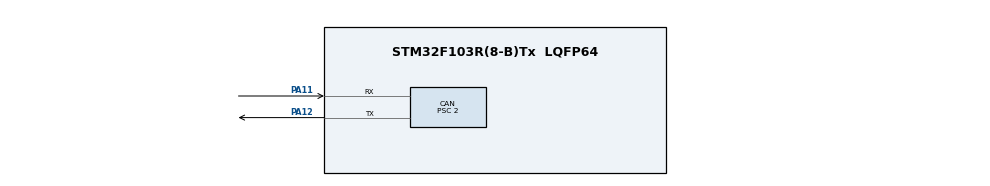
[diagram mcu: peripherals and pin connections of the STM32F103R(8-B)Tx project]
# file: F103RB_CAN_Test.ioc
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CAN.BS1=CAN_BS1_4TQ
CAN.BS2=CAN_BS2_3TQ
CAN.CalculateBaudRate=500000
CAN.CalculateTimeBit=2000.00
CAN.CalculateTimeQuantum=250.0
CAN.Mode=CAN_MODE_LOOPBACK
CAN.Prescaler=2
Mcu.Family=STM32F1
Mcu.Name=STM32F103R(8-B)Tx
Mcu.Package=LQFP64
NVIC.PriorityGroup=NVIC_PRIORITYGROUP_4
NVIC.USB_LP_CAN1_RX0_IRQn=true\:0\:0\:false\:false\:true\:true\:true
PA11.Mode=CAN_Activate
PA11.Signal=CAN_RX
PA12.Mode=CAN_Activate
PA12.Signal=CAN_TX
PA13.Mode=Trace_Asynchronous_SW
PA13.Signal=SYS_JTMS-SWDIO
PA14.Mode=Trace_Asynchronous_SW
PA14.Signal=SYS_JTCK-SWCLK
PB3.Mode=Trace_Asynchronous_SW
PB3.Signal=SYS_JTDO-TRACESWO
ProjectManager.HeapSize=0x200
ProjectManager.StackSize=0x400
ProjectManager.TargetToolchain=STM32CubeIDE
RCC.APB1Freq_Value=8000000
RCC.APB2Freq_Value=8000000
board=custom

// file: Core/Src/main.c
/* USER CODE BEGIN Header */
/**
  ******************************************************************************
  * @file           : main.c
  * @brief          : Main program body
  ******************************************************************************
  * @attention
  *
  * <h2><center>&copy; Copyright (c) 2022 STMicroelectronics.
  * All rights reserved.</center></h2>
  *
  * This software component is licensed by ST under BSD 3-Clause license,
  * the "License"; You may not use this file except in compliance with the
  * License. You may obtain a copy of the License at:
  *                        opensource.org/licenses/BSD-3-Clause
  *
  ******************************************************************************
  */
/* USER CODE END Header */
#include "main.h"

/* USER CODE BEGIN Includes */
#include <stdio.h>
/* USER CODE END Includes */

CAN_HandleTypeDef hcan;

/* USER CODE BEGIN PV */
CAN_FilterTypeDef canFilterConfig;  //can filter config
CAN_TxHeaderTypeDef TxHeader; //tx header
CAN_RxHeaderTypeDef RxHeader; //rx header
uint8_t TxData[8]; // = {0x01, 0x02, 0x03, 0x04, 0x05, 0x06, 0x07, 0x08}; //tx bufer
uint8_t RxData[8]; // = {0,0,0,0,0,0,0,0}; //rx buffer
uint32_t canMailbox; //mailbox holder
uint8_t count = 0;
/* USER CODE END PV */

void SystemClock_Config(void);
static void MX_GPIO_Init(void);
static void MX_CAN_Init(void);
/* USER CODE BEGIN PFP */
void Send_Debug(char *message, size_t len);
/* USER CODE END PFP */

/* USER CODE BEGIN 0 */

void HAL_CAN_RxFifo0MsgPendingCallback(CAN_HandleTypeDef *hcan)
{
	count++;
	HAL_CAN_GetRxMessage(hcan, CAN_RX_FIFO0, &RxHeader, RxData);
//	HAL_GPIO_TogglePin(LD1_GPIO_Port, LD1_Pin);
}

/* USER CODE END 0 */

int main(void)
{

  /* MCU Configuration--------------------------------------------------------*/

  /* Reset of all peripherals, Initializes the Flash interface and the Systick. */
  HAL_Init();

  /* Configure the system clock */
  SystemClock_Config();

  /* Initialize all configured peripherals */
  MX_GPIO_Init();
  MX_CAN_Init();
  /* USER CODE BEGIN 2 */
//  TxHeader.IDE = CAN_ID_STD; //use standard ID formats
//  TxHeader.StdId = 0x020; //ID of the transmitter
//  TxHeader.RTR = CAN_RTR_DATA; //data type for transmit frame
//  TxHeader.DLC = 2; //message size of two bytes

//  canFilterConfig.FilterActivation = CAN_FILTER_ENABLE;
//  canFilterConfig.FilterBank = 0;
//  canFilterConfig.FilterFIFOAssignment = CAN_FILTER_FIFO0;
//  canFilterConfig.FilterIdHigh = 0;
//  canFilterConfig.FilterIdLow = 0;
//  canFilterConfig.FilterMaskIdLow = 0x0000;
//  canFilterConfig.FilterMaskIdHigh = 0x0000;
//  canFilterConfig.FilterMode = CAN_FILTERMODE_IDMASK;
//  canFilterConfig.FilterScale = CAN_FILTERSCALE_32BIT;
//  canFilterConfig.SlaveStartFilterBank = 20;

  canFilterConfig.FilterActivation = CAN_FILTER_ENABLE;
  canFilterConfig.FilterBank = 10;
  canFilterConfig.FilterFIFOAssignment = CAN_FILTER_FIFO0;
  canFilterConfig.FilterIdHigh = 0;
  canFilterConfig.FilterIdLow = 0x0000;
  canFilterConfig.FilterMaskIdHigh = 0x0000;
  canFilterConfig.FilterMaskIdLow = 0x0000;
  canFilterConfig.FilterMode = CAN_FILTERMODE_IDMASK;
  canFilterConfig.FilterScale = CAN_FILTERSCALE_32BIT;
  canFilterConfig.SlaveStartFilterBank = 0;

  //Configuring CAN filter for CAN1
  HAL_CAN_ConfigFilter(&hcan, &canFilterConfig);
  //start can peripheral
  HAL_CAN_Start(&hcan);
  //inilitlize callback function
  HAL_CAN_ActivateNotification(&hcan, CAN_IT_RX_FIFO0_MSG_PENDING);

  TxHeader.DLC = 1; //message size of two bytes
	TxHeader.ExtId = 0;
	TxHeader.IDE = CAN_ID_STD; //use standard ID formats
	TxHeader.RTR = CAN_RTR_DATA; //data type for transmit frame
	TxHeader.StdId = 0x103; //ID of the transmitter
	TxHeader.TransmitGlobalTime = DISABLE;

    TxData[0] = 0xf3;

//  if (HAL_CAN_AddTxMessage(&hcan, &TxHeader, TxData, &canMailbox) != HAL_OK)
//  {
//	 Error_Handler ();
//  }

  /* USER CODE END 2 */

  /* Infinite loop */
  /* USER CODE BEGIN WHILE */
  while (1)
  {
	  //state message going to be send
//	  char msgBuf[100];
//	  sprintf(msgBuf, "CAN1 Attempting to send the following bytes over CAN: %hu, %hu, %hu, %hu, %hu, %hu, %hu, %hu.", TxData[0], TxData[1], TxData[2], TxData[3], TxData[4], TxData[5], TxData[6], TxData[7]);
//	  Send_Debug(msgBuf, 85);
	  //sending can message

//	  sprintf(msgBuf, "CAN1 message sent!");
//	  Send_Debug(msgBuf, 18);
	  if (HAL_CAN_AddTxMessage(&hcan, &TxHeader, TxData, &canMailbox) != HAL_OK)
		{
		 Error_Handler ();
		}
	  HAL_Delay(2000);
    /* USER CODE END WHILE */

  }
}

void SystemClock_Config(void)
{
  RCC_OscInitTypeDef RCC_OscInitStruct = {0};
  RCC_ClkInitTypeDef RCC_ClkInitStruct = {0};

  /** Initializes the RCC Oscillators according to the specified parameters
  * in the RCC_OscInitTypeDef structure.
  */
  RCC_OscInitStruct.OscillatorType = RCC_OSCILLATORTYPE_HSI;
  RCC_OscInitStruct.HSIState = RCC_HSI_ON;
  RCC_OscInitStruct.HSICalibrationValue = RCC_HSICALIBRATION_DEFAULT;
  RCC_OscInitStruct.PLL.PLLState = RCC_PLL_NONE;
  if (HAL_RCC_OscConfig(&RCC_OscInitStruct) != HAL_OK)
  {
    Error_Handler();
  }
  /** Initializes the CPU, AHB and APB buses clocks
  */
  RCC_ClkInitStruct.ClockType = RCC_CLOCKTYPE_HCLK|RCC_CLOCKTYPE_SYSCLK
                              |RCC_CLOCKTYPE_PCLK1|RCC_CLOCKTYPE_PCLK2;
  RCC_ClkInitStruct.SYSCLKSource = RCC_SYSCLKSOURCE_HSI;
  RCC_ClkInitStruct.AHBCLKDivider = RCC_SYSCLK_DIV1;
  RCC_ClkInitStruct.APB1CLKDivider = RCC_HCLK_DIV1;
  RCC_ClkInitStruct.APB2CLKDivider = RCC_HCLK_DIV1;

  if (HAL_RCC_ClockConfig(&RCC_ClkInitStruct, FLASH_LATENCY_0) != HAL_OK)
  {
    Error_Handler();
  }
}

static void MX_CAN_Init(void)
{

  hcan.Instance = CAN1;
  hcan.Init.Prescaler = 2;
  hcan.Init.Mode = CAN_MODE_LOOPBACK;
  hcan.Init.SyncJumpWidth = CAN_SJW_1TQ;
  hcan.Init.TimeSeg1 = CAN_BS1_4TQ;
  hcan.Init.TimeSeg2 = CAN_BS2_3TQ;
  hcan.Init.TimeTriggeredMode = DISABLE;
  hcan.Init.AutoBusOff = DISABLE;
  hcan.Init.AutoWakeUp = DISABLE;
  hcan.Init.AutoRetransmission = DISABLE;
  hcan.Init.ReceiveFifoLocked = DISABLE;
  hcan.Init.TransmitFifoPriority = DISABLE;
  if (HAL_CAN_Init(&hcan) != HAL_OK)
  {
    Error_Handler();
  }

}

static void MX_GPIO_Init(void)
{

  /* GPIO Ports Clock Enable */
  __HAL_RCC_GPIOA_CLK_ENABLE();
  __HAL_RCC_GPIOB_CLK_ENABLE();

}

/* USER CODE BEGIN 4 */
void Send_Debug(char *message, size_t len)
{
	for (int i = 0; i < len; i++)
	{
		ITM_SendChar(message[i]);
	}
	ITM_SendChar('\n');
}

//void HAL_CAN_RxFifo0MsgPendingCallback(CAN_HandleTypeDef *hcan1)
//{
//	if (HAL_CAN_GetRxMessage(hcan1, CAN_RX_FIFO0, &RxHeader, RxData) != HAL_OK)
//	{
//		Error_Handler();
//	}
//
//	char formatted[50];
//	//	HAL_GPIO_TogglePin(LD1_GPIO_Port, LD1_Pin);
//	sprintf(formatted, "Message Received on CAN2!");
//	Send_Debug(formatted, 25);
//	for(int i = 0; i < (sizeof(RxData)/sizeof(RxData[0])); i++) {
//	  sprintf(formatted, "%hu", RxData[i]);
//	  Send_Debug(formatted, 4);
//	}
//
//}
/* USER CODE END 4 */

void Error_Handler(void)
{
  __disable_irq();
  while (1)
  {
  }
}

/************************ (C) COPYRIGHT STMicroelectronics *****END OF FILE****/
